# c75_CMMU register map
Vendor: Texas Instruments
Peripheral module from a debugger description file (folder C75).
Registers are 64-bit, access per field, reset 0x0 unless marked. A register's access mark holds for its fields unless they carry their own. Offsets are as the file gives them; lines under a group give offsets from that group; [hi:lo] are bit positions; {n}, {i} and the like mark numbered series; 'fields as' and 'values as' point back to an identical list; <NAME> marks a mode.

## CMMU — Corepac Memory Management Unit
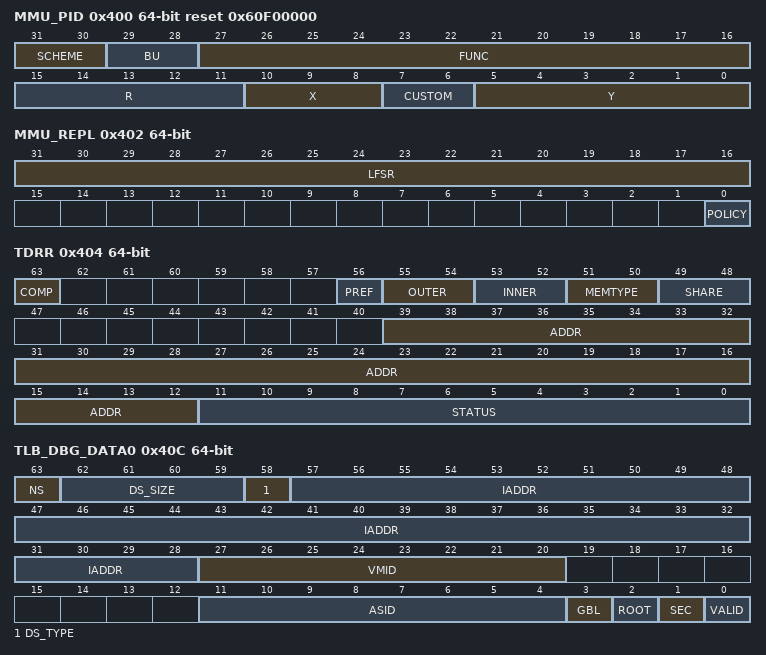
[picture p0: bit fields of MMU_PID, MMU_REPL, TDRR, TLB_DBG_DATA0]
0x400 MMU_PID ro reset 0x60F00000 — Physical ID Register
  [31:30] SCHEME — PID naming scheme
  [29:28] BU — Business Unit
  [27:16] FUNC — MMU Function code
  [15:11] R — Minor Revision
  [10:8] X — Architecture Revision
  [7:6] CUSTOM — Reuseable/Custom
  [5:0] Y — Configuration Revision
0x402 MMU_REPL — Replacement Policy Register
  [31:16] LFSR rw — LFSR Value
  [0] POLICY rw — Replacement Policy
0x404 TDRR — Translation Debug Response Register
  [63] COMP rw — Translation Completion Bit
  [56] PREF rw — Prefetchable
  [55:54] OUTER rw — Outer Cacheability
  [53:52] INNER rw — Inner Cacheability
  [51:50] MEMTYPE rw — Memory Type
  [49:48] SHARE rw — Shareability
  [39:12] ADDR rw — Output Address, Faulting Stage-2 IPA
  [11:0] STATUS rw — Translation Response Status
0x405 TDFAR rw — Translation Debug Fault Address Register
  [63:0] ADDR — Faulted Input Address
0x408 TLB_INV access not given reset not defined — TLB Invalidation Register
0x40A TLB_INVC — TLB Complete Register
  [0] COMP rw — Invalidation Completed
0x40B TLB_DBG access not given reset not defined — TLB Debug Access Register
0x40C TLB_DBG_DATA0 ro — TLB Debug Data 0 Register
  [63] NS — Non-Secure Page, NSTable accumulation
  [62:59] DS_SIZE — Descriptor Size
  [58] DS_TYPE — Descriptor Type
  [57:28] IADDR — Input Address
  [27:20] VMID
  [11:4] ASID
  [3] GBL — Global Page
  [2] ROOT — Root Context
  [1] SEC — Security Context
  [0] VALID — Valid Entry
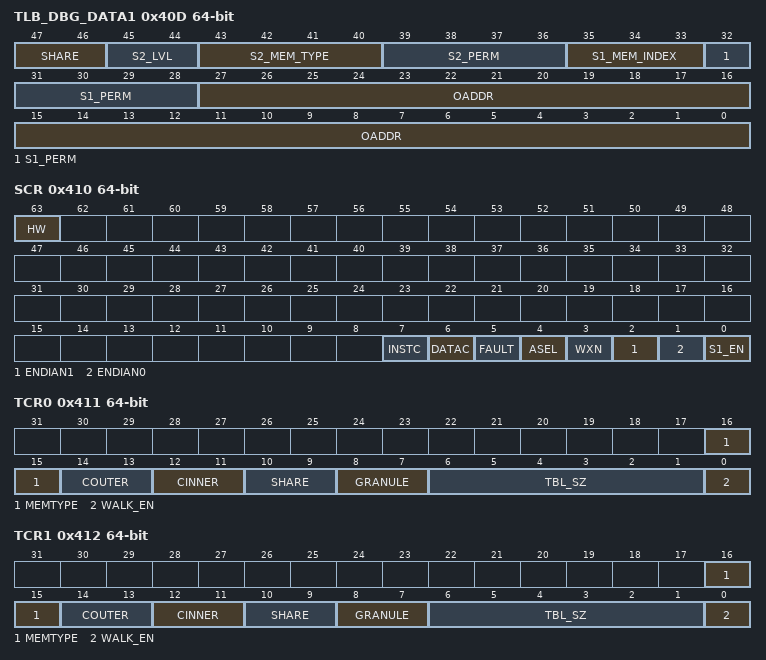
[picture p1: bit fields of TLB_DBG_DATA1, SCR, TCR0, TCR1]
0x40D TLB_DBG_DATA1 ro — TLB Debug Data 1 Register
  [47:46] SHARE — Shareability
  [45:44] S2_LVL — Stage 2 Level
  [43:40] S2_MEM_TYPE — Stage 2 Memory Type
  [39:36] S2_PERM — S2 Access Permissions
  [35:33] S1_MEM_INDEX — Stage 1 Memory Attribute Index
  [32:28] S1_PERM — Stage 1 Access Permissions
  [27:0] OADDR — Output Address
0x410 SCR — System Control Register\[Banked: Guest Supervisor, Supervisor, Secure Supervisor\]
  [63] HW rw — HW Mode
  [7] INSTC rw — Stage 1 Instruction Caching
  [6] DATAC rw — Stage 1 Data Caching
  [5] FAULT rw — Caching faults in uTLBs
  [4] ASEL rw — ASID Selection
  [3] WXN rw — Writeable memory Execute Never
  [2] ENDIAN1 rw — Stage 1 Region 1 Endian
  [1] ENDIAN0 rw — Stage 1 Region 0 Endian
  [0] S1_EN rw — Enable Stage 1 Address Translation
0x411 TCR0 — Table Control Register 0\[Banked: Guest Supervisor, Supervisor, Secure Supervisor\]
  [16:15] MEMTYPE rw — Memory Type of Translation Table Walks
  [14:13] COUTER rw — Outer Cacheability attribute of memory for Translation Table Walks
  [12:11] CINNER rw — Inner Cacheability attribute of memory for Translation Table Walks
  [10:9] SHARE rw — Shareability attribute of memory for Translation Table Walks
  [8:7] GRANULE rw — Translation Table Page Granule Size
  [6:1] TBL_SZ rw — Translation Table Region Size
  [0] WALK_EN rw — Enable Translation Table Walks
0x412 TCR1 — Table Control Register 1\[Banked: Guest Supervisor, Supervisor, Secure Supervisor\]
  fields as TCR0
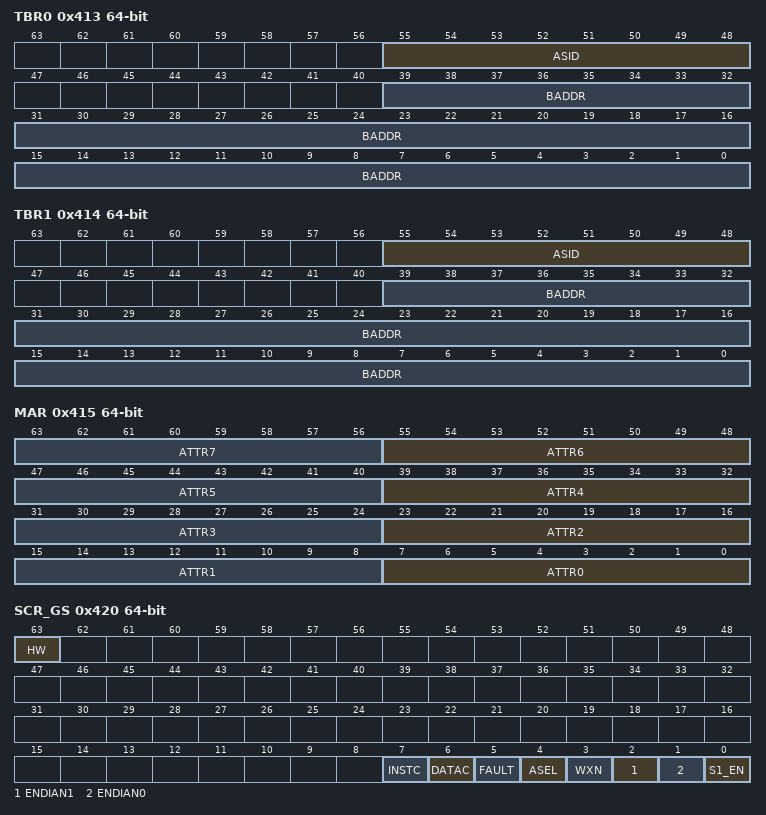
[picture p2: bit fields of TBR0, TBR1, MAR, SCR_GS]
0x413 TBR0 — Table Base Register 0\[Banked: Guest Supervisor, Supervisor, Secure Supervisor\]
  [55:48] ASID rw — Application Space ID
  [39:0] BADDR rw — Table Base Address
0x414 TBR1 — Table Base Register 1\[Banked: Guest Supervisor, Supervisor, Secure Supervisor\]
  fields as TBR0
0x415 MAR rw — Memory Attribute Register\[Banked: Guest Supervisor, Supervisor, Secure Supervisor\]
  [8n+7:8n] ATTR{n} (n=0..7) — Memory Attribute Index {n}
0x416 TDAR access not given reset not defined — Translation Debug Address Register\[Banked: Guest Supervisor, Supervisor, Secure Supervisor\]
0x420 SCR_GS — System Control Register - Non-Secure Guest Supervisor
  fields as SCR
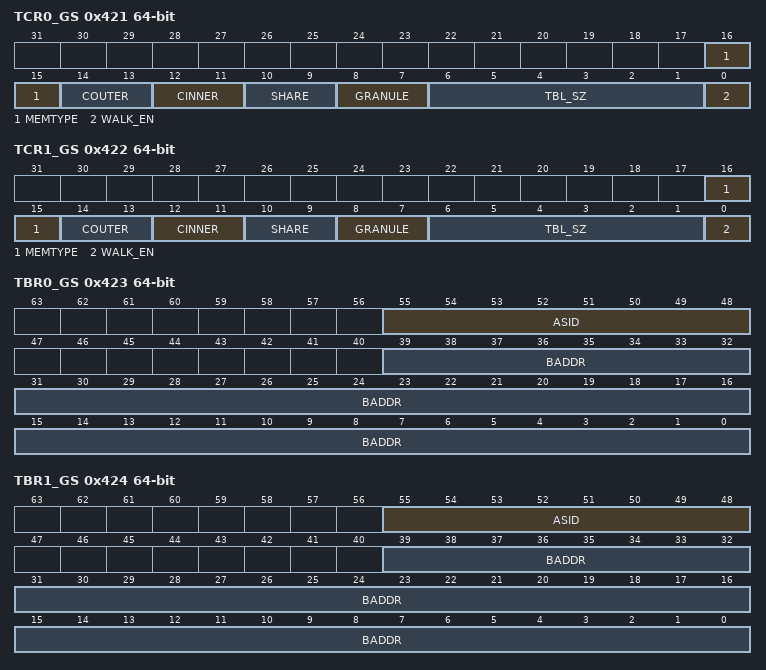
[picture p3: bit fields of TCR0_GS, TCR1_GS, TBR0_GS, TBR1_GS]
0x421 TCR0_GS — Table Control Register 0 - Non-Secure Guest Supervisor
  fields as TCR0
0x422 TCR1_GS — Table Control Register 1 - Non-Secure Guest Supervisor
  fields as TCR0
0x423 TBR0_GS — Table Base Register 0 - Non-Secure Guest Supervisor
  fields as TBR0
0x424 TBR1_GS — Table Base Register 1 - Non-Secure Guest Supervisor
  fields as TBR0
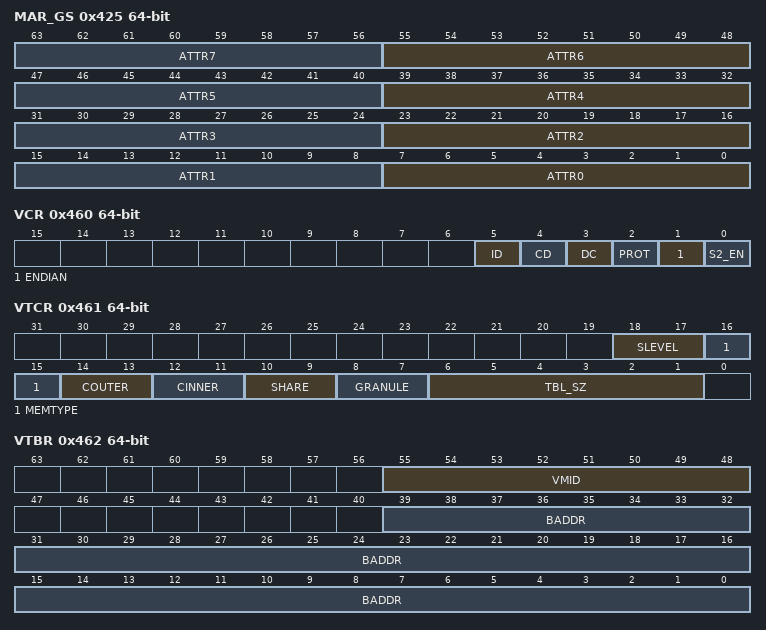
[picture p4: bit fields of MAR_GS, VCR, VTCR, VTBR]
0x425 MAR_GS rw — Memory Attribute Register - Non-Secure Guest Supervisor
  [8n+7:8n] ATTR{n} (n=0..7) — Memory Attribute Index {n}
0x426 TDAR_GS access not given reset not defined — Translation Debug Address Register - Non-Secure Guest Supervisor
0x436 TDAR_S access not given reset not defined — Translation Debug Address Register - Non-Secure Supervisor
0x460 VCR — Virtualization Control Register
  [5] ID rw — Stage 2 Instruction Cache Disable
  [4] CD rw — Stage 2 Data Cache Disable
  [3] DC rw — Default Cacheable Mode
  [2] PROT rw — Protected Table Walk
  [1] ENDIAN rw — Stage 2 Endian
  [0] S2_EN rw — Enable Stage 2 Address Translation
0x461 VTCR — Virtualization Table Control Register
  [18:17] SLEVEL rw — Stage 2 Starting Translation Level
  [16:15] MEMTYPE rw — Memory Type of Translation Table Walks
  [14:13] COUTER rw — Outer Cacheability attribute of memory for Translation Table Walks
  [12:11] CINNER rw — Inner Cacheability attribute of memory for Translation Table Walks
  [10:9] SHARE rw — Shareability attribute of memory for Translation Table Walks
  [8:7] GRANULE rw — Translation Table Page Granule Size
  [6:1] TBL_SZ rw — Translation Table Region Size
0x462 VTBR — Virtualization Table Base Register
  [55:48] VMID rw — Virtual Machine ID
  [39:0] BADDR rw — Table Base Address
0x463 VTDAR access not given reset not defined — Virtualization Translation Debug Address Register
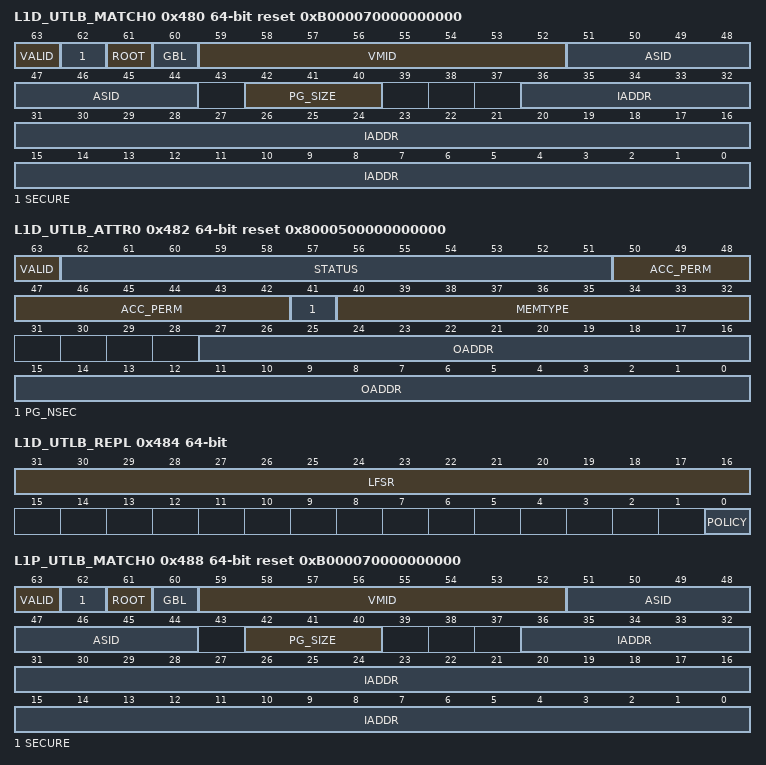
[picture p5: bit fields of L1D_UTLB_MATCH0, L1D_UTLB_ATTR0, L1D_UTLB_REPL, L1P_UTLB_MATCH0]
0x480 L1D_UTLB_MATCH0 reset 0xB000070000000000 — uTLB Page Match Entry Index 0
  [63] VALID rw — Entry Valid
  [62] SECURE rw — Secure Page
  [61] ROOT rw — Root Page
  [60] GBL rw — Global Page
  [59:52] VMID rw
  [51:44] ASID rw
  [42:40] PG_SIZE rw — Page Size
  [36:0] IADDR rw — Input Address
0x482 L1D_UTLB_ATTR0 reset 0x8000500000000000 — uTLB Page Attribute Entry Index 0
  [63] VALID rw — Entry Valid
  [62:51] STATUS rw — TLB Status
  [50:42] ACC_PERM rw — Access Permissions
  [41] PG_NSEC rw — Page Non-Secure
  [40:32] MEMTYPE rw — Page Memory Type
  [27:0] OADDR rw — Output Address
0x484 L1D_UTLB_REPL — uTLB Replacement Policy Register
  [31:16] LFSR rw — LFSR Value
  [0] POLICY rw — Replacement Policy
0x488 L1P_UTLB_MATCH0 reset 0xB000070000000000 — uTLB Page Match Entry Index 0
  fields as L1D_UTLB_MATCH0
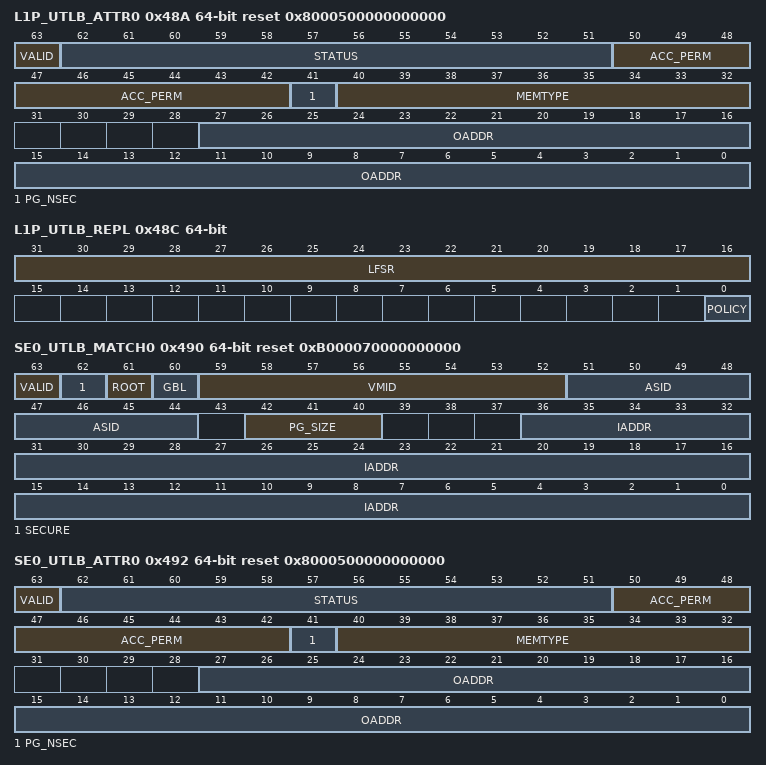
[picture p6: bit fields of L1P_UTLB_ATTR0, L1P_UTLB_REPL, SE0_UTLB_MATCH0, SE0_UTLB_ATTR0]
0x48A L1P_UTLB_ATTR0 reset 0x8000500000000000 — uTLB Page Attribute Entry Index 0
  fields as L1D_UTLB_ATTR0
0x48C L1P_UTLB_REPL — uTLB Replacement Policy Register
  [31:16] LFSR rw — LFSR Value
  [0] POLICY rw — Replacement Policy
0x490 SE0_UTLB_MATCH0 reset 0xB000070000000000 — uTLB Page Match Entry Index 0
  fields as L1D_UTLB_MATCH0
0x492 SE0_UTLB_ATTR0 reset 0x8000500000000000 — uTLB Page Attribute Entry Index 0
  fields as L1D_UTLB_ATTR0
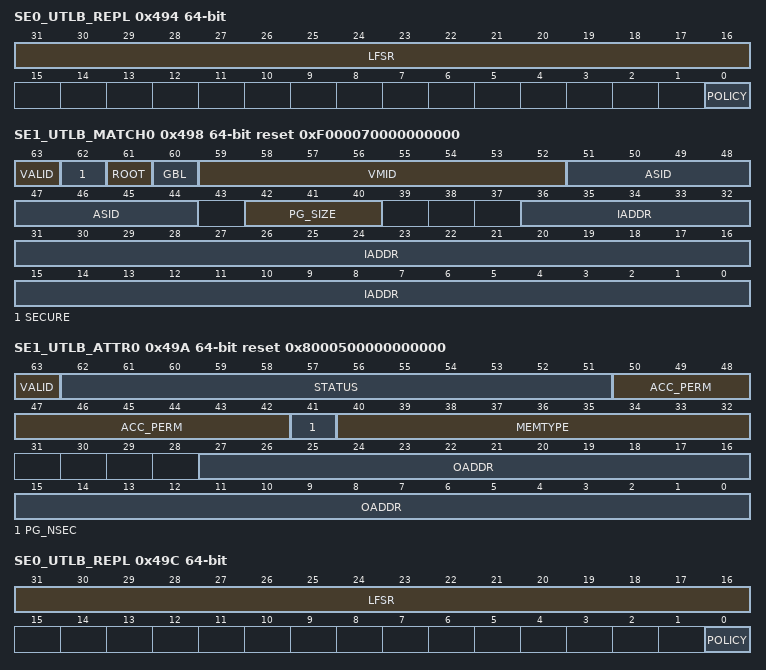
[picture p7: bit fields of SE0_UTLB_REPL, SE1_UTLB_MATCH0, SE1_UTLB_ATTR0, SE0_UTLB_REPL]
0x494 SE0_UTLB_REPL — uTLB Replacement Policy Register
  [31:16] LFSR rw — LFSR Value
  [0] POLICY rw — Replacement Policy
0x498 SE1_UTLB_MATCH0 reset 0xF000070000000000 — uTLB Page Match Entry Index 0
  fields as L1D_UTLB_MATCH0
0x49A SE1_UTLB_ATTR0 reset 0x8000500000000000 — uTLB Page Attribute Entry Index 0
  fields as L1D_UTLB_ATTR0
0x49C SE0_UTLB_REPL — uTLB Replacement Policy Register
  [31:16] LFSR rw — LFSR Value
  [0] POLICY rw — Replacement Policy
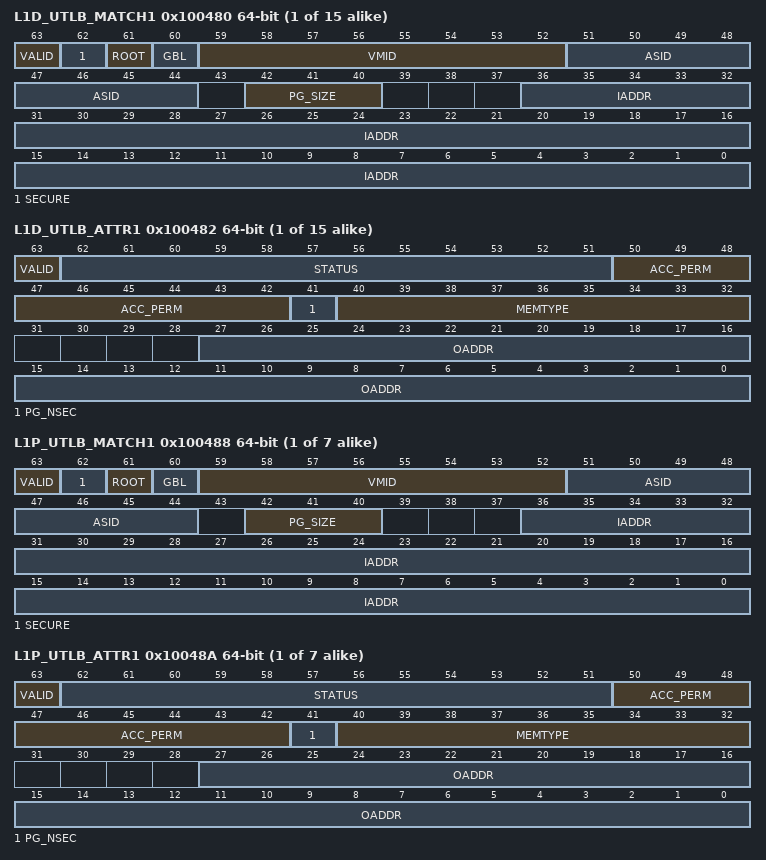
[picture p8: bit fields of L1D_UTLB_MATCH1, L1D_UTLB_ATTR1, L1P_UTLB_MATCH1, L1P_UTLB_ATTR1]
{0x480+0x100000*i} L1D_UTLB_MATCH{i} (i=1..15) — uTLB Page Match Entry Index {i}
  fields as L1D_UTLB_MATCH0
{0x482+0x100000*i} L1D_UTLB_ATTR{i} (i=1..15) — uTLB Page Attribute Entry Index {i}
  fields as L1D_UTLB_ATTR0
{0x488+0x100000*i} L1P_UTLB_MATCH{i} (i=1..7) — uTLB Page Match Entry Index {i}
  fields as L1D_UTLB_MATCH0
{0x48A+0x100000*i} L1P_UTLB_ATTR{i} (i=1..7) — uTLB Page Attribute Entry Index {i}
  fields as L1D_UTLB_ATTR0
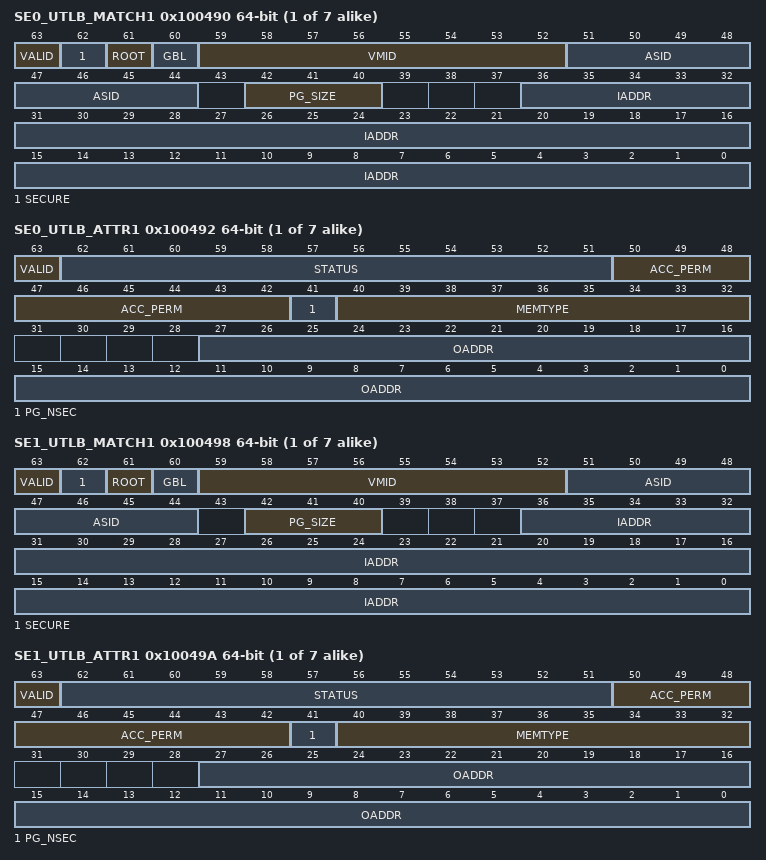
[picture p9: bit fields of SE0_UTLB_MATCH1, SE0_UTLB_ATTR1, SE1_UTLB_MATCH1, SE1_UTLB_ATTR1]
{0x490+0x100000*i} SE0_UTLB_MATCH{i} (i=1..7) — uTLB Page Match Entry Index {i}
  fields as L1D_UTLB_MATCH0
{0x492+0x100000*i} SE0_UTLB_ATTR{i} (i=1..7) — uTLB Page Attribute Entry Index {i}
  fields as L1D_UTLB_ATTR0
{0x498+0x100000*i} SE1_UTLB_MATCH{i} (i=1..7) — uTLB Page Match Entry Index {i}
  fields as L1D_UTLB_MATCH0
{0x49A+0x100000*i} SE1_UTLB_ATTR{i} (i=1..7) — uTLB Page Attribute Entry Index {i}
  fields as L1D_UTLB_ATTR0
